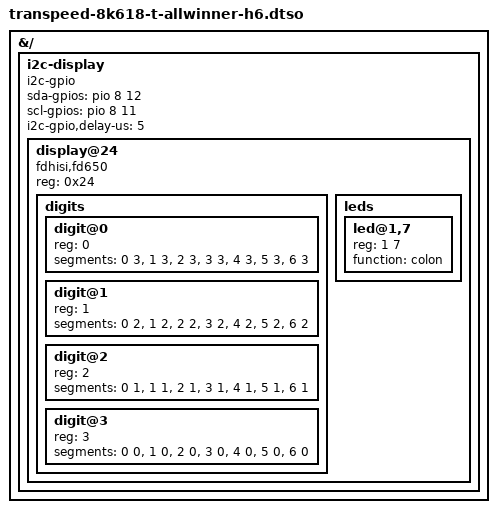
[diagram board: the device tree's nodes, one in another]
/dts-v1/;
/plugin/;

#include <dt-bindings/gpio/gpio.h>
#include <dt-bindings/leds/common.h>

&{/} {
	i2c-display {
		compatible = "i2c-gpio";
		sda-gpios = <&pio 8 12 (GPIO_ACTIVE_HIGH|GPIO_OPEN_DRAIN)>; /* PI12 */
		scl-gpios = <&pio 8 11 (GPIO_ACTIVE_HIGH|GPIO_OPEN_DRAIN)>; /* PI11 */
		i2c-gpio,delay-us = <5>;
#address-cells = <1>;
#size-cells = <0>;

		display@24 {
			compatible = "fdhisi,fd650", "titanmec,tm1650";
			reg = <0x24>;
			digits {
				#address-cells = <1>;
				#size-cells = <0>;
				digit@0 {
					reg = <0>;
					segments = <0 3>,
						   <1 3>,
						   <2 3>,
						   <3 3>,
						   <4 3>,
						   <5 3>,
						   <6 3>;
				};
				digit@1 {
					reg = <1>;
					segments = <0 2>,
						   <1 2>,
						   <2 2>,
						   <3 2>,
						   <4 2>,
						   <5 2>,
						   <6 2>;
				};
				digit@2 {
					reg = <2>;
					segments = <0 1>,
						   <1 1>,
						   <2 1>,
						   <3 1>,
						   <4 1>,
						   <5 1>,
						   <6 1>;
				};
				digit@3 {
					reg = <3>;
					segments = <0 0>,
						   <1 0>,
						   <2 0>,
						   <3 0>,
						   <4 0>,
						   <5 0>,
						   <6 0>;
				};
			};

			leds {
				#address-cells = <2>;
				#size-cells = <0>;
				led@1,7 {
					reg = <1 7>;
					function = "colon";
				};
			};
		};
	};
};
